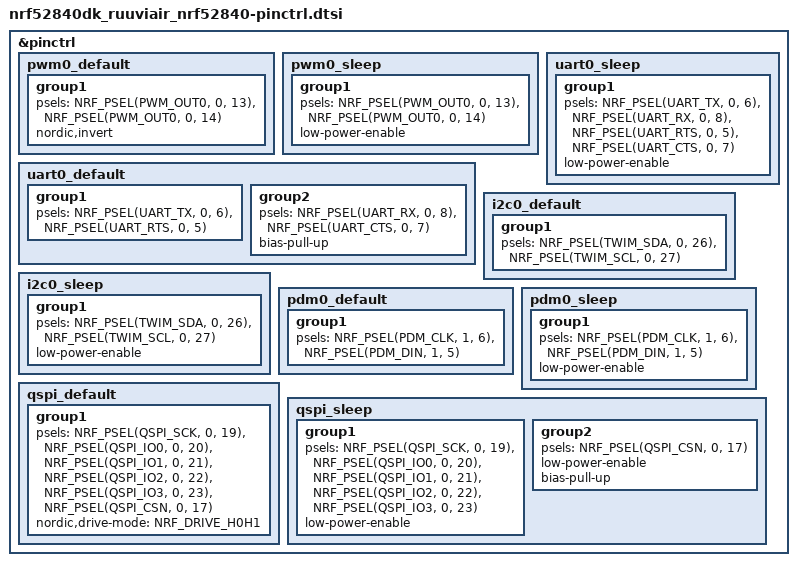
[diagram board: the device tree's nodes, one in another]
/*
 * Copyright (c) 2022 Nordic Semiconductor
 * SPDX-License-Identifier: Apache-2.0
 */

&pinctrl {
	pwm0_default: pwm0_default {
		group1 {
			psels =
				<NRF_PSEL(PWM_OUT0, 0, 13)>,
				<NRF_PSEL(PWM_OUT0, 0, 14)>;
			nordic,invert;
		};
	};

	pwm0_sleep: pwm0_sleep {
		group1 {
			psels =
				<NRF_PSEL(PWM_OUT0, 0, 13)>,
				<NRF_PSEL(PWM_OUT0, 0, 14)>;
			low-power-enable;
		};
	};

	uart0_default: uart0_default {
		group1 {
			psels =
				<NRF_PSEL(UART_TX, 0, 6)>,
				<NRF_PSEL(UART_RTS, 0, 5)>;
		};

		group2 {
			psels =
				<NRF_PSEL(UART_RX, 0, 8)>,
				<NRF_PSEL(UART_CTS, 0, 7)>;
			bias-pull-up;
		};
	};

	uart0_sleep: uart0_sleep {
		group1 {
			psels =
				<NRF_PSEL(UART_TX, 0, 6)>,
				<NRF_PSEL(UART_RX, 0, 8)>,
				<NRF_PSEL(UART_RTS, 0, 5)>,
				<NRF_PSEL(UART_CTS, 0, 7)>;
			low-power-enable;
		};
	};

	i2c0_default: i2c0_default {
		group1 {
			psels =
				<NRF_PSEL(TWIM_SDA, 0, 26)>,
				<NRF_PSEL(TWIM_SCL, 0, 27)>;
		};
	};

	i2c0_sleep: i2c0_sleep {
		group1 {
			psels =
				<NRF_PSEL(TWIM_SDA, 0, 26)>,
				<NRF_PSEL(TWIM_SCL, 0, 27)>;
			low-power-enable;
		};
	};

	pdm0_default: pdm0_default {
		group1 {
			psels =
				<NRF_PSEL(PDM_CLK, 1, 6)>,
				<NRF_PSEL(PDM_DIN, 1, 5)>;
		};
	};

	pdm0_sleep: pdm0_sleep {
		group1 {
			psels =
				<NRF_PSEL(PDM_CLK, 1, 6)>,
				<NRF_PSEL(PDM_DIN, 1, 5)>;
			low-power-enable;
		};
	};

	qspi_default: qspi_default {
		group1 {
			psels =
				<NRF_PSEL(QSPI_SCK, 0, 19)>,
				<NRF_PSEL(QSPI_IO0, 0, 20)>,
				<NRF_PSEL(QSPI_IO1, 0, 21)>,
				<NRF_PSEL(QSPI_IO2, 0, 22)>,
				<NRF_PSEL(QSPI_IO3, 0, 23)>,
				<NRF_PSEL(QSPI_CSN, 0, 17)>;
			nordic,drive-mode = <NRF_DRIVE_H0H1>;
		};
	};

	qspi_sleep: qspi_sleep {
		group1 {
			psels =
				<NRF_PSEL(QSPI_SCK, 0, 19)>,
				<NRF_PSEL(QSPI_IO0, 0, 20)>,
				<NRF_PSEL(QSPI_IO1, 0, 21)>,
				<NRF_PSEL(QSPI_IO2, 0, 22)>,
				<NRF_PSEL(QSPI_IO3, 0, 23)>;
			low-power-enable;
		};

		group2 {
			psels = <NRF_PSEL(QSPI_CSN, 0, 17)>;
			low-power-enable;
			bias-pull-up;
		};
	};
};
